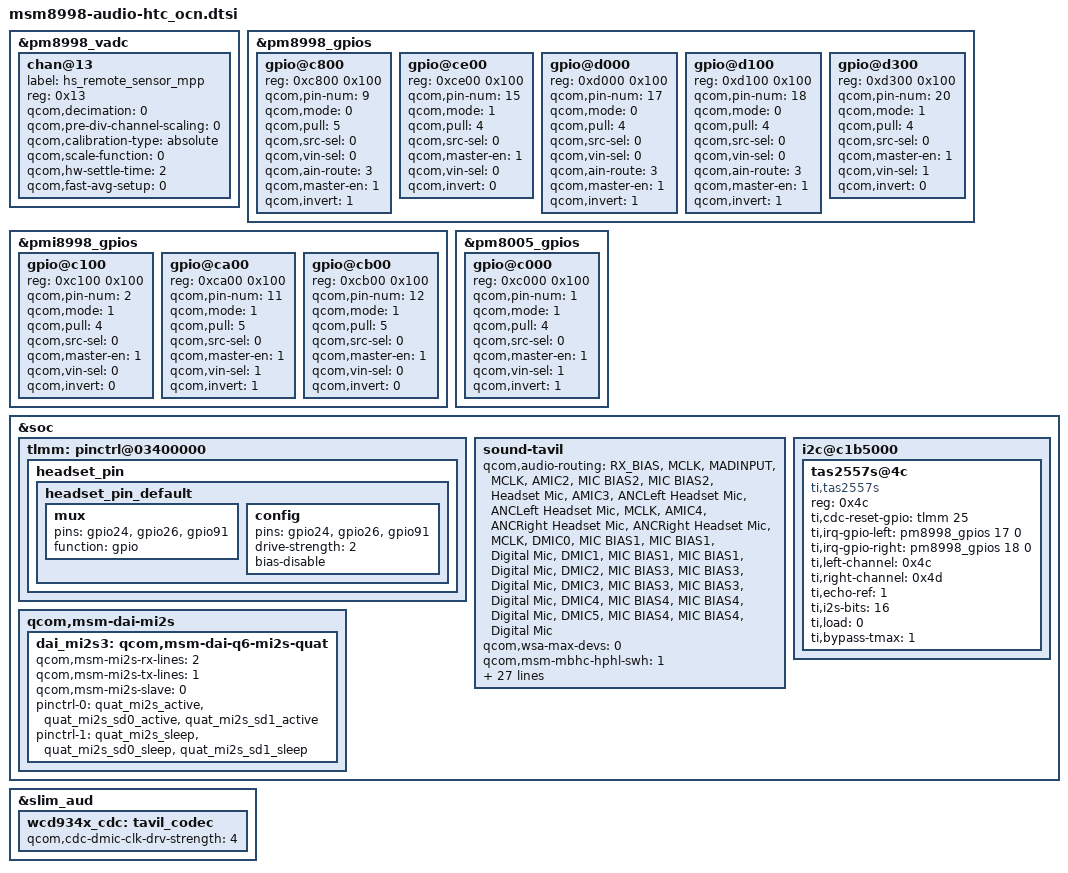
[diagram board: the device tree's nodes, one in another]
/* 8996 Ocean Audio Config */

&pm8998_vadc {
	chan@13 {
		label = "hs_remote_sensor_mpp";
		reg = <0x13>;
		qcom,decimation = <0>;			//512 sampling rate
		qcom,pre-div-channel-scaling = <0>;	//1:1 scaling
		qcom,calibration-type = "absolute";	//Use 625mV & 1.25V reference voltage
		qcom,scale-function = <0>;		//convert raw adc code to voltage
		qcom,hw-settle-time = <2>;		//200us
		qcom,fast-avg-setup = <0>;		//with only 1 average measurement
	};
};

&pm8998_gpios {
	gpio@c800 { /* AUD_REMO_SENSOR */
		reg = <0xc800 0x100>;
		qcom,pin-num = <9>;
		qcom,mode = <0>;		/* Digital input */
		qcom,pull = <5>;		/* No Pull */
		qcom,src-sel = <0>;		/* QPNP_PIN_SEL_FUNC_CONSTANT */
		qcom,vin-sel = <0>;
		qcom,ain-route = <3>;		/* QPNP_PIN_AIN_AMUX_CH */
		qcom,master-en = <1>;		/* Enable GPIO */
		qcom,invert = <1>;
		status = "okay";
	};

	gpio@ce00 { /* AUD_HSMIC_2V85_EN */
		reg = <0xce00 0x100>;
		qcom,pin-num = <15>;
		qcom,mode = <1>;		/* Digital output */
		qcom,pull = <4>;		/* Pull Down */
		qcom,src-sel = <0>;		/* GPIO */
		qcom,master-en = <1>;		/* Enable GPIO */
		qcom,vin-sel = <0>;
		qcom,invert = <0>;
		status = "okay";
	};

	gpio@d000 { /* AUD_TI_IRQ_1 */
		reg = <0xd000 0x100>;
		qcom,pin-num = <17>;
		qcom,mode = <0>;		/* Digital input */
		qcom,pull = <4>;		/* Pull Down */
		qcom,src-sel = <0>;		/* QPNP_PIN_SEL_FUNC_CONSTANT */
		qcom,vin-sel = <0>;
		qcom,ain-route = <3>;		/* QPNP_PIN_AIN_AMUX_CH */
		qcom,master-en = <1>;		/* Enable GPIO */
		qcom,invert = <1>;
		status = "okay";
	};

	gpio@d100 { /* AUD_TI_IRQ_2 */
		reg = <0xd100 0x100>;
		qcom,pin-num = <18>;
		qcom,mode = <0>;		/* Digital input */
		qcom,pull = <4>;		/* Pull Down */
		qcom,src-sel = <0>;		/* QPNP_PIN_SEL_FUNC_CONSTANT */
		qcom,vin-sel = <0>;
		qcom,ain-route = <3>;		/* QPNP_PIN_AIN_AMUX_CH */
		qcom,master-en = <1>;		/* Enable GPIO */
		qcom,invert = <1>;
		status = "okay";
	};

	gpio@d300 { /* AUD_MICLR_DGND_SW_EN */
		reg = <0xd300 0x100>;
		qcom,pin-num = <20>;
		qcom,mode = <1>;		/* Digital output */
		qcom,pull = <4>;		/* Pull Down */
		qcom,src-sel = <0>;		/* GPIO */
		qcom,master-en = <1>;		/* Enable GPIO */
		qcom,vin-sel = <1>;
		qcom,invert = <0>;
		status = "okay";
	};
};

&pmi8998_gpios {
	gpio@c100 { /* USB_HPH_FSA3030_SEL2 */
		reg = <0xc100 0x100>;
		qcom,pin-num = <2>;
		qcom,mode = <1>;		/* Digital output */
		qcom,pull = <4>;		/* Pull Down */
		qcom,src-sel = <0>;		/* GPIO */
		qcom,master-en = <1>;		/* Enable GPIO */
		qcom,vin-sel = <0>;
		qcom,invert = <0>;
		status = "okay";
	};

	gpio@ca00 { /* AUD_HPMIC_AGND_FLIP_EN_S1 */
		reg = <0xca00 0x100>;
		qcom,pin-num = <11>;
		qcom,mode = <1>;		/* Digital output */
		qcom,pull = <5>;		/* No Pull */
		qcom,src-sel = <0>;		/* GPIO */
		qcom,master-en = <1>;		/* Enable GPIO */
		qcom,vin-sel = <1>;
		qcom,invert = <1>;		/* Output High */
		status = "okay";
	};

	gpio@cb00 { /* AUD_HPMIC_AGND_FLIP_EN_S0 */
		reg = <0xcb00 0x100>;
		qcom,pin-num = <12>;
		qcom,mode = <1>;		/* Digital output */
		qcom,pull = <5>;		/* No Pull */
		qcom,src-sel = <0>;		/* GPIO */
		qcom,master-en = <1>;		/* Enable GPIO */
		qcom,vin-sel = <0>;
		qcom,invert = <0>;
		status = "okay";
	};
};

&pm8005_gpios {
	gpio@c000 { /* AUD_3V3_EN */
		reg = <0xc000 0x100>;
		qcom,pin-num = <1>;
		qcom,mode = <1>;		/* Digital output */
		qcom,pull = <4>;		/* Pull Down */
		qcom,src-sel = <0>;		/* GPIO */
		qcom,master-en = <1>;		/* Enable GPIO */
		qcom,vin-sel = <1>;
		qcom,invert = <1>;
		status = "okay";
	};
};

&soc {
	tlmm: pinctrl@03400000 {
		/*type-C headset ID1, ID2, Flip position*/
		headset_pin {
			headset_pin_default: headset_pin_default {
				mux {
					pins = "gpio24", "gpio26", "gpio91";
					function = "gpio";
				};
				config {
					pins = "gpio24", "gpio26", "gpio91";
					drive-strength = <2>; /* 2 mA */
					bias-disable;       /* NO PULL */
				};
			};

		};
	};

	sound-tavil {
		qcom,audio-routing =
			"RX_BIAS", "MCLK",
			"MADINPUT", "MCLK",
			"AMIC2", "MIC BIAS2",
			"MIC BIAS2", "Headset Mic",
/* HTC_AUD_START */
			"AMIC3", "ANCLeft Headset Mic",
			"ANCLeft Headset Mic", "MCLK",
			"AMIC4", "ANCRight Headset Mic",
			"ANCRight Headset Mic", "MCLK",
			"DMIC0", "MIC BIAS1",
			"MIC BIAS1", "Digital Mic",
			"DMIC1", "MIC BIAS1",
			"MIC BIAS1", "Digital Mic",
			"DMIC2", "MIC BIAS3",
			"MIC BIAS3", "Digital Mic",
			"DMIC3", "MIC BIAS3",
			"MIC BIAS3", "Digital Mic",
			"DMIC4", "MIC BIAS4",
			"MIC BIAS4", "Digital Mic",
			"DMIC5", "MIC BIAS4",
			"MIC BIAS4", "Digital Mic";
/* HTC_AUD_END */

		qcom,wsa-max-devs = <0>; /* No wsa device */
		/delete-property/ qcom,wsa-devs;
		/delete-property/ qcom,usbc-analog-en1_gpio;
		/delete-property/ qcom,usbc-analog-en2_n_gpio;
		/delete-property/ qcom,us-euro-gpios;
		/delete-property/ qcom,hph-en0-gpio;
		/delete-property/ qcom,hph-en1-gpio;

		qcom,msm-mbhc-hphl-swh = <1>; /* 1 for NO, 0 for NC */
		qcom,msm-mbhc-gnd-swh = <1>; /* 1 for NO, 0 for NC */

		mbhc-swap-detect = <0>; /* Disable MBHC SWAP detection */

		htc,aud_gpio_ids = "htc,aud_typec_id1",
				"htc,aud_typec_id2",
				"htc,aud_usb_position";

		htc,aud_gpio_switches = "htc,hpmic_agnd_flip_en_s0",
				"htc,hpmic_agnd_flip_en_s1",
				"htc,miclr_flip_en",
				"htc,miclr_dgnd_sw_en";

		htc,aud_3v3_en = <&pm8005_gpios 1 0>;
		htc,aud_usb_position = <&tlmm 91 0>;
		htc,aud_typec_id1 = <&tlmm 24 0>;
		htc,aud_typec_id2 = <&tlmm 26 0>;
		htc,hpmic_agnd_flip_en_s0= <&pmi8998_gpios 12 0>;
		htc,hpmic_agnd_flip_en_s1= <&pmi8998_gpios 11 0>;
		htc,miclr_flip_en = <&tlmm 29 0>;
		htc,miclr_dgnd_sw_en = <&pm8998_gpios 20 0>;
		htc,hsmic_2v85_en = <&pm8998_gpios 15 0>;
		htc,aud_remote_sensor = <&pm8998_gpios 9 0>;
		htc,typec-hs-pre-condition = <1>;

		htc,adapter_35mm_threshold = <330 800>;
		htc,adapter_25mm_threshold = <1250 2850>;

		htc,headset_adc_channel = <19>;
		qcom,headset-vadc = <&pm8998_vadc>;

		pinctrl-names = "default";
		pinctrl-0 = <&headset_pin_default>;

/*		htc,mbhc_hsdet_l = <&tlmm 27 0>; */
		htc,usb_hph_fsa3030_sel0 = <&tlmm 9 0>;
		htc,usb_hph_fsa3030_sel1 = <&tlmm 31 0>;
		htc,usb_hph_fsa3030_sel2 = <&pmi8998_gpios 2 0>;
	};

/* TI config for spk chip */
	i2c@c1b5000 { /* i2c_7 */
		tas2557s@4c {
			compatible = "ti,tas2557s";
			reg = <0x4c>;
			ti,cdc-reset-gpio = <&tlmm 25 0>;
			ti,irq-gpio-left = <&pm8998_gpios 17 0>;
			ti,irq-gpio-right = <&pm8998_gpios 18 0>;
			ti,left-channel = <0x4c>;
			ti,right-channel = <0x4d>;
			ti,echo-ref = <1>;   /* 0, left channel; 1, right channel; 2, both */
			ti,i2s-bits = <16>;   /* support 16, 24, 32 */
			ti,load = <0>;   /* 0, 8Ohm; 1, 6Ohm; 2, 4Ohm */
			ti,bypass-tmax = <1>;   /* 0, not bypass; 1, bypass */
			status = "ok";
		};
	};

	qcom,msm-dai-mi2s {
		dai_mi2s3: qcom,msm-dai-q6-mi2s-quat {
			qcom,msm-mi2s-rx-lines = <2>; /* SD1 (1 << 1) */
			qcom,msm-mi2s-tx-lines = <1>; /* SD0 (0 << 0) */
			qcom,msm-mi2s-slave = <0>;
			pinctrl-names = "default", "sleep";
			pinctrl-0 = <&quat_mi2s_active
				     &quat_mi2s_sd0_active
				     &quat_mi2s_sd1_active>;
			pinctrl-1 = <&quat_mi2s_sleep
				     &quat_mi2s_sd0_sleep
				     &quat_mi2s_sd1_sleep>;
		};
	};
	/delete-node/ msm_cdc_pinctrl@59;
	/delete-node/ msm_cdc_pinctrl@60;
};

&slim_aud {
	wcd934x_cdc: tavil_codec {
		qcom,cdc-dmic-clk-drv-strength = <4>;
	};
	tavil_codec {
		/delete-node/ swr_master;
	};
};
